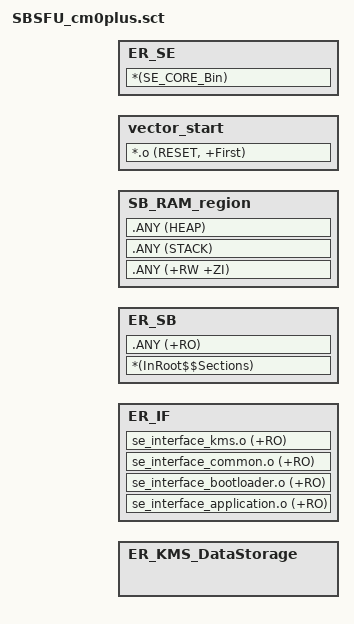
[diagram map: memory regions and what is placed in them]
#! armclang --target=arm-arm-none-eabi  -mcpu=cortex-m0plus -E -xc
; *************************************************************
; *** Scatter-Loading Description File generated by uVision ***
; *************************************************************
#include "..\..\Linker_Common\MDK-ARM\mapping_sbsfu.h"
#include "..\..\Linker_Common\MDK-ARM\mapping_fwimg.h"

; *** regions needed by SBSFU project ***

LR_KMS_DataStorage KMS_DATASTORAGE_START KMS_DATASTORAGE_SIZE {
  ER_KMS_DataStorage KMS_DATASTORAGE_START FILL 0X00000000 KMS_DATASTORAGE_SIZE {
  }
}

LR_IF SE_IF_REGION_ROM_START SE_IF_ROM_REGION_SIZE {
  ER_IF SE_IF_REGION_ROM_START SE_IF_ROM_REGION_SIZE {
  se_interface_application.o (+RO)
  se_interface_bootloader.o (+RO)
  se_interface_common.o (+RO)
  se_interface_kms.o (+RO)
  }
}

LR_SB SB_REGION_ROM_START SB_ROM_REGION_SIZE {  
  ER_SB SB_REGION_ROM_START SB_ROM_REGION_SIZE {
  *(InRoot$$Sections)
  .ANY (+RO)
  }
  SB_RAM_region SB_REGION_RAM_START SB_RAM_REGION_SIZE  {
  .ANY (+RW +ZI)
  .ANY (STACK)
  .ANY (HEAP)
  }
}

LR_ROM_Vector INTVECT_START VECTOR_SIZE {
  vector_start INTVECT_START VECTOR_SIZE {
  *.o (RESET, +First)
  }
}

LR_SE SE_CODE_REGION_ROM_START SE_ROM_REGION_SIZE {
  ER_SE SE_CODE_REGION_ROM_START SE_ROM_REGION_SIZE {
  *(SE_CORE_Bin)
  }
}


